# SF32LB57x register map
File version: 1.0
CPU: CM33 r0p1, little endian, MPU, FPU, 3 interrupt priority bits
Registers are 32-bit, read-write, reset 0x0 unless marked. A register's access mark holds for its fields unless they carry their own. Offsets are from the block's base; [hi:lo] are bit positions; 'fields as' and 'values as' point back to an identical list.

## MPI1
Base 0x50041000
Same registers: MPI2 0x50042000, MPI3 0x50043000
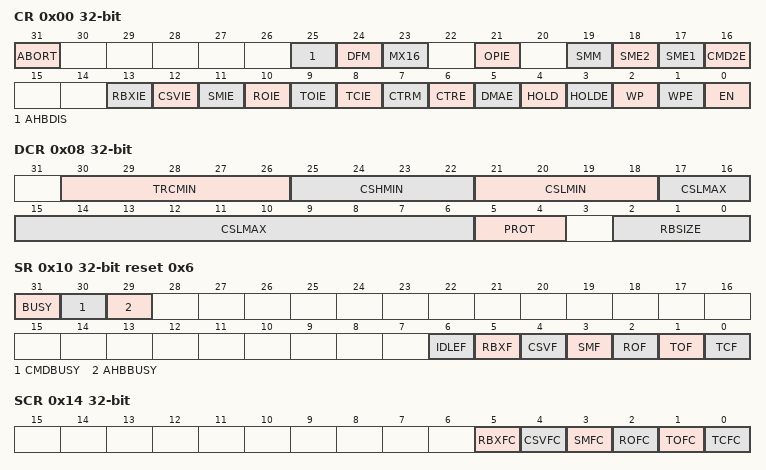
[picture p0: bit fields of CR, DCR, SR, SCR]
0x00 CR — Control Register
  [31] ABORT
  [25] AHBDIS — Hold hreadyout low if AHB access
  [24] DFM — Dual Flash Mode
  [23] MX16 — Mode X16
  [21] OPIE — OPI interface enable
  [19] SMM — Status match mode: 0 - AND mode; 1 - OR mode
  [18] SME2
  [17] SME1 — Status match enable. SME[0] enables CMD1, SME[1] enable CMD2. Only one CMD can be used as SM CMD
  [16] CMD2E — Enable CMD2. If set to 1, CMD2 will be issued after CMD1 with an interval of TI2
  [13] RBXIE — Row boundary crossing interrupt enable
  [12] CSVIE — CS max violation interrupt enable
  [11] SMIE — Status match interrupt enable
  [10] ROIE — Rx FIFO overflow interrupt enable
  [9] TOIE — Tx FIFO overflow interrupt enable
  [8] TCIE — Transfer complete interrupt enable
  [7] CTRM — AES-CTR mode. 0 - AES128, 1 - AES256
  [6] CTRE — AES-CTR on-the-fly decryption enable
  [5] DMAE — DMA enable in FIFO mode
  [4] HOLD — The value of HOLD when HOLDE is set
  [3] HOLDE — Enable HOLD function on IO3. Use this only in SPI or Dual SPI mode
  [2] WP — The value of WP when WPE is set
  [1] WPE — Enable WP function on IO2. Use this only in SPI or Dual SPI mode
  [0] EN — Enable MPI
0x04 DR — Data Register
  [31:0] DATA
0x08 DCR — Device Control Register
  [30:26] TRCMIN — Write/Read cycle minimum time
  [25:22] CSHMIN — Minimum CS high deselect time. 0 - one cycle, 1 - two cycles, etc.
  [21:18] CSLMIN — Minimum CS low active time. N - (n+1) cycles
  [17:6] CSLMAX — Maximum CS low active time. 0 - no limit, n - (n+1) cycles
  [5:4] PROT — Interface protocol 2'h0: Xccela 2'h1: Xccela legacy protocol 2'h2: HyperBus 2'h3: UpSRAM
  [2:0] RBSIZE — Row boundary size. 0 - no row boundary, n - row boundary at 2^(n+3) bytes
0x0C PSCLR — Prescaler Register
  [7:0] DIV — FCLK divided by DIV. 0/1 - SCLK=FCLK, 2 - SCLK=FCLK/2, n - SCLK=FCLK/n
0x10 SR reset 0x6 — Status Register
  [31] BUSY — For internal debug use only
  [30] CMDBUSY — For internal debug use only
  [29] AHBBUSY — For internal debug use only
  [6] IDLEF — Idle flag
  [5] RBXF — Row boundary crossing flag
  [4] CSVF — CS max violation flag
  [3] SMF — Status match flag in Polling Mode
  [2] ROF — Rx FIFO overflow flag
  [1] TOF — Tx FIFO overflow flag
  [0] TCF — Transfer complete flag
0x14 SCR — Status Clear Register
  [5] RBXFC
  [4] CSVFC
  [3] SMFC
  [2] ROFC
  [1] TOFC
  [0] TCFC — Write 1 to clear corresponding flag in SR
0x18 CMDR1 — Command Register
  [7:0] CMD — command
0x1C AR1 — Address Register
  [31:0] ADDR — address to be sent to the external Flash memory
0x20 ABR1 — Alternate Byte Register
  [31:0] ABYTE — Alternate byte
0x24 DLR1 — Data Length Register
  [19:0] DLEN — 0 - one byte to be transferred; 1 - two bytes
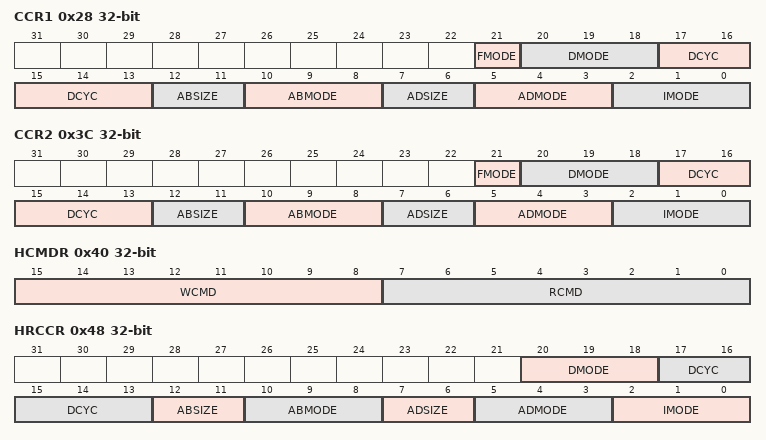
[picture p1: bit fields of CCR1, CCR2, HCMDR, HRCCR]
0x28 CCR1 — Communication Configuration Register
  [21] FMODE — 0 - read mode, 1 - write mode
  [20:18] DMODE
  [17:13] DCYC
  [12:11] ABSIZE
  [10:8] ABMODE
  [7:6] ADSIZE
  [5:3] ADMODE — Address mode
  [2:0] IMODE — Instruction mode. 0 - No instruction; 1 - single line; 2 - two lines; 3 - four lines; 4/5/6 - reserved; 7 - four lines DDR
0x2C CMDR2 — Command Register
  [7:0] CMD — command
0x30 AR2 — Address Register
  [31:0] ADDR — address to be sent to the external Flash memory
0x34 ABR2 — Alternate Byte Register
  [31:0] ABYTE — Alternate byte
0x38 DLR2 — Data Length Register
  [19:0] DLEN — 0 - one byte to be transferred; 1 - two bytes
0x3C CCR2 — Communication Configuration Register
  fields as CCR1
0x40 HCMDR — AHB Command Register
  [15:8] WCMD — During XIP, the AHB write transaction will be translated into this Write Command on SPI interface
  [7:0] RCMD — During XIP, the AHB read transaction will be translated into this Read Command on SPI interface
0x44 HRABR — AHB Read Alternate Byte Register
  [31:0] ABYTE
0x48 HRCCR — AHB Read Communication Configuration Register
  [20:18] DMODE
  [17:13] DCYC
  [12:11] ABSIZE
  [10:8] ABMODE
  [7:6] ADSIZE
  [5:3] ADMODE — Address mode
  [2:0] IMODE — Instruction mode. 0 - No instruction; 1 - single line; 2 - two lines; 3 - four lines; 4/5/6 - reserved; 7 - four lines DDR
0x4C HWABR — AHB Write Alternate Byte Register
  [31:0] ABYTE
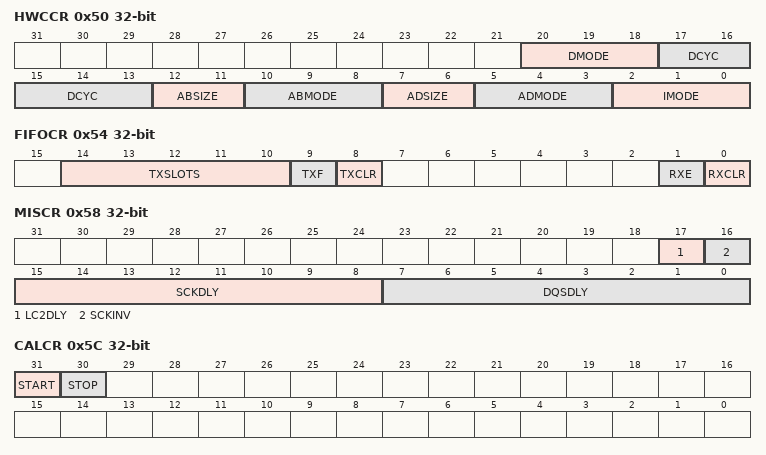
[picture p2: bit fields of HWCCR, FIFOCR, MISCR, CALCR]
0x50 HWCCR — AHB Write Communication Configuration Register
  fields as HRCCR
0x54 FIFOCR — FIFO Control Register
  [14:10] TXSLOTS — When DMA enabled, asserts DMA reqeust if TXFIFO vacant slots is greater than or equal to TXSLOTS
  [9] TXF — Tx FIFO full
  [8] TXCLR — write 1 to clear Tx FIFO
  [1] RXE — Rx FIFO empty
  [0] RXCLR — write 1 to clear Rx FIFO
0x58 MISCR — Miscelaneous Register
  [17] LC2DLY — For HyperRAM only. If set to 2, delay one cycle to see whether it's LCx1 or LCx2
  [16] SCKINV — For SDR FLASH only
  [15:8] SCKDLY — Used to adjust the output clock delay. Effective 7-bit, bypassed if MSB is set. For DTR FLASH and PSRAM use.
  [7:0] DQSDLY — Used to adjust the input sampling delay. Effective 7-bit, bypassed if MSB is set. For SDR/DTR FLASH, internal clock can be fine-tuned to match the input data delay For PSRAM, it should be configured such that DQS edge is in the middle of the input DQ data
0x5C CALCR — Calibration Control Register
  [31] START — Write 1 to start calibration
  [30] STOP — Write 1 to stop calibration
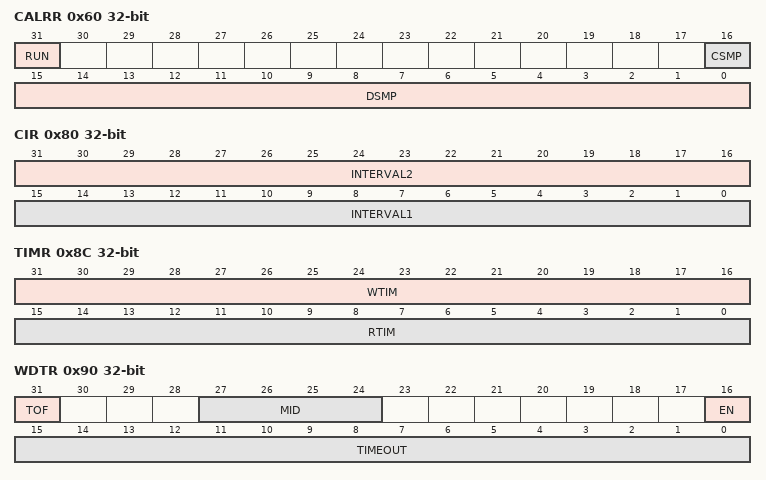
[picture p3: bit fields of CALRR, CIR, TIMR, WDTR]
0x60 CALRR — Calibration Result Register
  [31] RUN, [16] CSMP, [15:0] DSMP
0x64 CTRSAR — CTR Starting Address Register
  [31:10] SA
0x68 CTREAR — CTR Ending Address Register
  [31:10] EA
0x6C NONCEA
0x70 NONCEB
0x74 AASAR — Address Aliasing Start Address Register
  [31:10] SA — Starting address of the address aliasing area
0x78 AAEAR — Address Aliasing Ending Address Register
  [31:10] EA — Ending address of the address aliasing area
0x7C AAOAR — Address Aliasing Offset Address Register
  [31:10] OA — If address falls into the aliasing area, this offset will be added to the orignal address for SPI access
0x80 CIR — Command Interval Register
  [31:16] INTERVAL2, [15:0] INTERVAL1
0x84 SMR — Status Match Register
  [31:0] STATUS
0x88 SMKR — Status Mask Register
  [31:0] MASK — 0 - not considered; 1 - considered
0x8C TIMR — Timer Register
  [31:16] WTIM
  [15:0] RTIM — If set to 0, SPI will return to IDLE right after operation. Otherwise, keep CS active until timeout or new SPI operation triggers
0x90 WDTR — WDT Register
  [31] TOF — Timeout flag. Self cleared when the HREADYOUT being monitored becomes ready
  [27:24] MID
  [16] EN — WDT enable
  [15:0] TIMEOUT — Set AHB timeout value in number of clk_wdt cycles
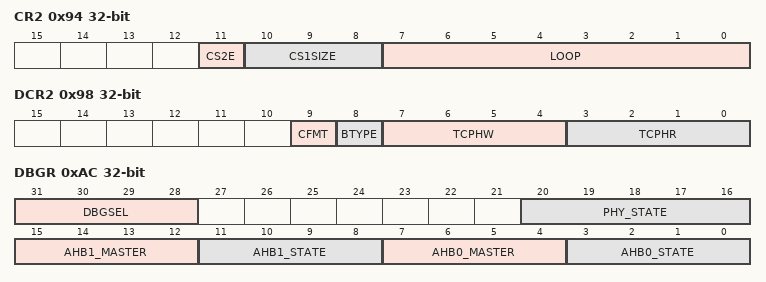
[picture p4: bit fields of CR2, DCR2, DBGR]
0x94 CR2 — Control Register 2
  [11] CS2E — Force CS2 enable
  [10:8] CS1SIZE — 0 - unlimited, 1 - 4Mb, 2 - 8Mb, 3 - 16Mb, 4 - 32Mb, 5 - 64Mb, 6 - 128Mb, 7 - 256Mb
  [7:0] LOOP — Loop CMD1/CMD2
0x98 DCR2 — Device Control Register 2
  [9] CFMT — Commond format for UpSRAM only. Keep at 0, reserved for future use
  [8] BTYPE — Burst type, set to 0 for 32Mb HyperRAM only
  [7:4] TCPHW — For AMP32 only
  [3:0] TCPHR — For APM32 only
0x9C CTRSAR2 — CTR Starting Address Register 2
  [31:10] SA
0xA0 CTREAR2 — CTR Ending Address Register 2
  [31:10] EA
0xA4 NONCEA2 — Nonce A Register 2
  [31:0] NONCEA
0xA8 NONCEB2 — Nonce B Register 2
  [31:0] NONCEB
0xAC DBGR — Debug Register
  [31:28] DBGSEL, [20:16] PHY_STATE, [15:12] AHB1_MASTER, [11:8] AHB1_STATE, [7:4] AHB0_MASTER, [3:0] AHB0_STATE
